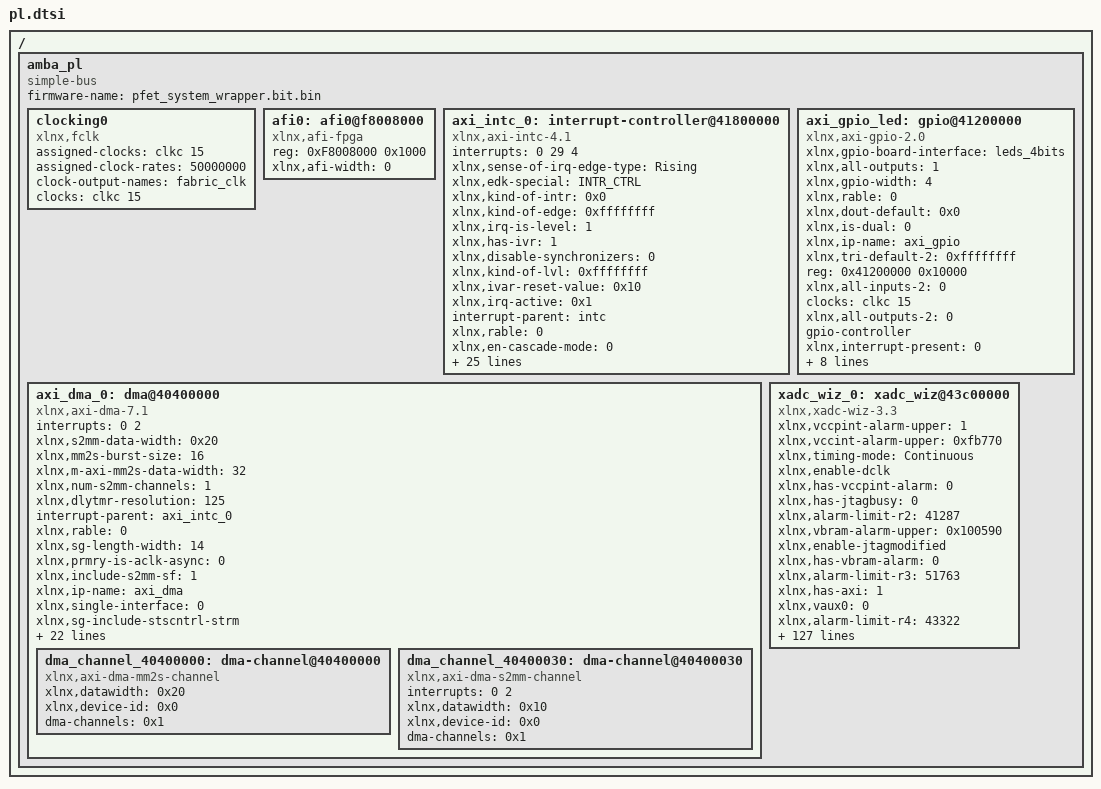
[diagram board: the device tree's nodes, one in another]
/ {
	amba_pl: amba_pl {
		ranges;
		compatible = "simple-bus";
		#address-cells = <1>;
		#size-cells = <1>;
		firmware-name = "pfet_system_wrapper.bit.bin";
		clocking0: clocking0 {
			compatible = "xlnx,fclk";
			assigned-clocks = <&clkc 15>;
			assigned-clock-rates = <50000000>;
			#clock-cells = <0>;
			clock-output-names = "fabric_clk";
			clocks = <&clkc 15>;
		};
		afi0: afi0@f8008000 {
			status = "okay";
			compatible = "xlnx,afi-fpga";
			#address-cells = <1>;
			reg = <0xF8008000 0x1000>;
			#size-cells = <0>;
			xlnx,afi-width = <0>;
		};
		axi_intc_0: interrupt-controller@41800000 {
			#interrupt-cells = <2>;
			interrupts = < 0 29 4 >;
			xlnx,sense-of-irq-edge-type = "Rising";
			xlnx,edk-special = "INTR_CTRL";
			xlnx,kind-of-intr = <0x0>;
			xlnx,kind-of-edge = <0xffffffff>;
			xlnx,irq-is-level = <1>;
			xlnx,has-ivr = <1>;
			compatible = "xlnx,axi-intc-4.1" , "xlnx,xps-intc-1.00.a";
			xlnx,disable-synchronizers = <0>;
			xlnx,kind-of-lvl = <0xffffffff>;
			xlnx,ivar-reset-value = <0x10>;
			xlnx,irq-active = <0x1>;
			interrupt-parent = <&intc>;
			xlnx,rable = <0>;
			xlnx,en-cascade-mode = <0>;
			xlnx,ip-name = "axi_intc";
			xlnx,has-ilr = <0>;
			reg = <0x41800000 0x10000>;
			xlnx,addr-width = <0x20>;
			clocks = <&clkc 15>;
			xlnx,s-axi-aclk-freq-mhz = <50>;
			xlnx,num-sw-intr = <0>;
			xlnx,irq-connection = <1>;
			xlnx,num-intr-inputs = <0x1>;
			xlnx,has-sie = <1>;
			xlnx,enable-async = <0>;
			xlnx,has-cie = <1>;
			xlnx,num-sync-ff = <2>;
			xlnx,edk-iptype = "PERIPHERAL";
			xlnx,mb-clk-not-connected = <1>;
			xlnx,has-ipr = <1>;
			xlnx,sense-of-irq-level-type = "Active_High";
			xlnx,cascade-master = <0>;
			xlnx,processor-clk-freq-mhz = <100>;
			status = "okay";
			xlnx,is-fast = <0x0>;
			clock-names = "s_axi_aclk";
			xlnx,has-fast = <0>;
			xlnx,ivar-rst-val = <0x10>;
			interrupt-controller;
			interrupt-names = "irq";
			xlnx,async-intr = <0xfffffffe>;
			xlnx,name = "axi_intc_0";
		};
		axi_dma_0: dma@40400000 {
			interrupts = < 0 2 >;
			compatible = "xlnx,axi-dma-7.1" , "xlnx,axi-dma-1.00.a";
			xlnx,s2mm-data-width = <0x20>;
			xlnx,mm2s-burst-size = <16>;
			xlnx,m-axi-mm2s-data-width = <32>;
			xlnx,num-s2mm-channels = <1>;
			xlnx,dlytmr-resolution = <125>;
			interrupt-parent = <&axi_intc_0>;
			xlnx,rable = <0>;
			xlnx,sg-length-width = <14>;
			xlnx,prmry-is-aclk-async = <0>;
			xlnx,include-s2mm-sf = <1>;
			#dma-cells = <1>;
			xlnx,ip-name = "axi_dma";
			xlnx,single-interface = <0>;
			xlnx,sg-include-stscntrl-strm;
			xlnx,include-s2mm-dre = <0>;
			reg = <0x40400000 0x10000>;
			xlnx,addr-width = <32>;
			xlnx,include-s2mm = <1>;
			clocks = <&clkc 15>, <&clkc 15>, <&clkc 15>, <&clkc 15>;
			xlnx,s-axis-s2mm-tdata-width = <16>;
			xlnx,micro-dma = <0>;
			xlnx,increase-throughput = <0>;
			xlnx,mm2s-data-width = <0x20>;
			xlnx,addrwidth = <0x20>;
			xlnx,include-sg;
			xlnx,sg-use-stsapp-length = <0>;
			xlnx,m-axis-mm2s-tdata-width = <32>;
			xlnx,edk-iptype = "PERIPHERAL";
			xlnx,s2mm-burst-size = <16>;
			xlnx,m-axi-s2mm-data-width = <32>;
			xlnx,num-mm2s-channels = <1>;
			xlnx,enable-multi-channel = <0>;
			status = "okay";
			xlnx,include-mm2s-sf = <1>;
			clock-names = "m_axi_mm2s_aclk" , "m_axi_s2mm_aclk" , "m_axi_sg_aclk" , "s_axi_lite_aclk";
			interrupt-names = "s2mm_introut";
			xlnx,include-mm2s = <1>;
			xlnx,include-mm2s-dre = <0>;
			xlnx,name = "axi_dma_0";
			dma_channel_40400000: dma-channel@40400000 {
				xlnx,datawidth = <0x20>;
				xlnx,device-id = <0x0>;
				compatible = "xlnx,axi-dma-mm2s-channel";
				dma-channels = <0x1>;
			};
			dma_channel_40400030: dma-channel@40400030 {
				interrupts = <0 2>;
				xlnx,datawidth = <0x10>;
				xlnx,device-id = <0x0>;
				compatible = "xlnx,axi-dma-s2mm-channel";
				dma-channels = <0x1>;
			};
		};
		axi_gpio_led: gpio@41200000 {
			xlnx,gpio-board-interface = "leds_4bits";
			compatible = "xlnx,axi-gpio-2.0" , "xlnx,xps-gpio-1.00.a";
			xlnx,all-outputs = <1>;
			#gpio-cells = <2>;
			xlnx,gpio-width = <4>;
			xlnx,rable = <0>;
			xlnx,dout-default = <0x0>;
			xlnx,is-dual = <0>;
			xlnx,ip-name = "axi_gpio";
			xlnx,tri-default-2 = <0xffffffff>;
			reg = <0x41200000 0x10000>;
			xlnx,all-inputs-2 = <0>;
			clocks = <&clkc 15>;
			xlnx,all-outputs-2 = <0>;
			gpio-controller;
			xlnx,interrupt-present = <0>;
			xlnx,gpio2-board-interface = "Custom";
			xlnx,edk-iptype = "PERIPHERAL";
			xlnx,dout-default-2 = <0x0>;
			status = "okay";
			xlnx,gpio2-width = <32>;
			clock-names = "s_axi_aclk";
			xlnx,use-board-flow;
			xlnx,tri-default = <0xffffffff>;
			xlnx,name = "axi_gpio_led";
			xlnx,all-inputs = <0>;
		};
		xadc_wiz_0: xadc_wiz@43c00000 {
			xlnx,vccpint-alarm-upper = <1>;
			xlnx,vccint-alarm-upper = <0xfb770>;
			xlnx,timing-mode = "Continuous";
			xlnx,enable-dclk;
			xlnx,has-vccpint-alarm = <0>;
			xlnx,has-jtagbusy = <0>;
			xlnx,alarm-limit-r2 = <41287>;
			xlnx,vbram-alarm-upper = <0x100590>;
			xlnx,enable-jtagmodified;
			xlnx,has-vbram-alarm = <0>;
			xlnx,alarm-limit-r3 = <51763>;
			xlnx,has-axi = <1>;
			xlnx,vaux0 = <0>;
			xlnx,alarm-limit-r4 = <43322>;
			xlnx,has-busy = <1>;
			xlnx,enable-channel;
			xlnx,vaux1 = <0>;
			xlnx,has-vccaux-alarm = <0>;
			xlnx,alarm-limit-r5 = <21190>;
			xlnx,dclk-frequency = <100>;
			xlnx,rable = <0>;
			xlnx,vaux2 = <0>;
			xlnx,alarm-limit-r6 = <38229>;
			xlnx,vaux3 = <0>;
			xlnx,has-drp = <0>;
			xlnx,ip-name = "xadc_wiz";
			xlnx,alarm-limit-r7 = <44622>;
			xlnx,configuration-r0 = <0>;
			xlnx,vaux4 = <0>;
			xlnx,sim-file-rel-path = "./";
			reg = <0x43c00000 0x10000>;
			xlnx,alarm-limit-r8 = <22937>;
			xlnx,configuration-r1 = <8623>;
			xlnx,external-mux-channel = "VP_VN";
			xlnx,temperature-alarm-trigger = <85>;
			xlnx,vaux5 = <0>;
			xlnx,has-jtaglocked = <0>;
			xlnx,alarm-limit-r9 = <20753>;
			xlnx,configuration-r2 = <1024>;
			xlnx,vaux6 = <1>;
			xlnx,vaux7 = <1>;
			xlnx,vaux8 = <0>;
			xlnx,vaux9 = <0>;
			xlnx,vaux10 = <0>;
			xlnx,has-vn = <1>;
			xlnx,has-vccpaux-alarm = <0>;
			xlnx,acquisition-time = <4>;
			xlnx,vaux11 = <0>;
			xlnx,has-temp-bus = <0>;
			xlnx,xadc-starup-selection = "channel_sequencer";
			xlnx,enable-busy;
			xlnx,data-width = <32>;
			xlnx,vaux12 = <0>;
			xlnx,sim-file-sel = "Default";
			xlnx,has-vp = <1>;
			xlnx,channel-enable-vauxp14-vauxn14;
			xlnx,ip-type = <0x0>;
			xlnx,temperature-alarm-ot-reset = <70>;
			xlnx,vaux13 = <0>;
			xlnx,enable-convst;
			xlnx,vaux14 = <1>;
			xlnx,channel-enable-vauxp15-vauxn15;
			xlnx,vccpaux-alarm-lower = <0x1a17b0>;
			xlnx,vccaux-alarm-lower = <0x1ab3f0>;
			xlnx,vaux15 = <1>;
			compatible = "xlnx,xadc-wiz-3.3" , "xlnx,axi-xadc-1.00.a";
			xlnx,has-external-mux = <0>;
			xlnx,sampling-rate = <0x7fffffff>;
			xlnx,has-reset = <0>;
			xlnx,adc-conversion-rate = <1000>;
			xlnx,vccddro-alarm-lower = <0x124f80>;
			xlnx,enable-calibration-averaging;
			xlnx,has-user-temp-alarm = <0>;
			xlnx,enable-axi4stream;
			xlnx,has-ot-alarm = <0>;
			xlnx,has-convst = <0>;
			xlnx,single-channel-selection = "TEMPERATURE";
			xlnx,startup-channel-selection = "single_channel";
			xlnx,interface-selection = "Enable_AXI";
			xlnx,vccpaux-alarm-upper = <0x1b7740>;
			xlnx,vccaux-alarm-upper = <0x1cd6d0>;
			status = "okay";
			xlnx,sensor-offset-and-gain-calibration;
			xlnx,vccddro-alarm-upper = <0x1312d0>;
			xlnx,name = "xadc_wiz_0";
			xlnx,external-mux = "none";
			xlnx,enable-eoc;
			xlnx,enable-jtaglocked;
			xlnx,sim-file-name = "design";
			xlnx,temperature-alarm-reset = <60>;
			xlnx,addr-width = <32>;
			clocks = <&clkc 15>, <&clkc 15>;
			xlnx,alarm-limit-r10 = <21845>;
			xlnx,alarm-limit-r11 = <20753>;
			xlnx,alarm-limit-r12 = <39321>;
			xlnx,edk-iptype = "PERIPHERAL";
			xlnx,alarm-limit-r13 = <37355>;
			xlnx,sequencer-mode = "Continuous";
			xlnx,enable-jtagbusy;
			xlnx,alarm-limit-r14 = <27306>;
			xlnx,include-intr = <1>;
			xlnx,alarm-limit-r15 = <26214>;
			xlnx,fifo-depth = <7>;
			clock-names = "s_axi_aclk" , "s_axis_aclk";
			xlnx,has-eoc = <1>;
			xlnx,temperature-alarm-ot-trigger = <125>;
			xlnx,average-enable-vauxp14-vauxn14;
			xlnx,has-channel = <1>;
			xlnx,enable-eos;
			xlnx,average-enable-vauxp15-vauxn15;
			xlnx,channel-enable-vauxp7-vauxn7;
			xlnx,average-enable-vauxp7-vauxn7;
			xlnx,vccpint-alarm-lower = <0xe7ef0>;
			xlnx,vccint-alarm-lower = <0xecd10>;
			xlnx,has-dclk = <1>;
			xlnx,vbram-alarm-lower = <0xe7ef0>;
			xlnx,num-wave = <1>;
			xlnx,sequence-r0 = <0>;
			xlnx,has-jtagmodified = <0>;
			xlnx,sequence-r1 = <49344>;
			xlnx,channel-enable-vauxp6-vauxn6;
			xlnx,enable-drp;
			xlnx,sequence-r2 = <0>;
			xlnx,has-vccint-alarm = <0>;
			xlnx,channel-averaging = "None";
			xlnx,sequence-r3 = <49344>;
			xlnx,average-enable-vauxp6-vauxn6;
			xlnx,has-axi4stream = <1>;
			xlnx,sequence-r4 = <0>;
			xlnx,sequence-r5 = <0>;
			xlnx,adc-offset-and-gain-calibration;
			xlnx,waveform-type = "CONSTANT";
			xlnx,sequence-r6 = <0>;
			xlnx,vccddro-volt = "1_2";
			xlnx,sequence-r7 = <0>;
			xlnx,has-vccddro-alarm = <0>;
			xlnx,has-eos = <1>;
			xlnx,alarm-limit-r0 = <46573>;
			xlnx,has-convstclk = <0>;
			xlnx,stimulus-freq = <1>;
			xlnx,single-channel-enable-calibration;
			xlnx,alarm-limit-r1 = <22500>;
			xlnx,component-name = "pfet_system_xadc_wiz_0_0";
			xlnx,external-muxaddr-enable = <0>;
		};
	};
};
